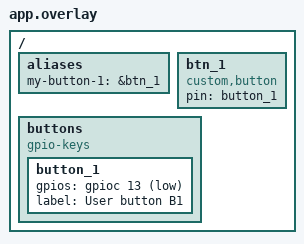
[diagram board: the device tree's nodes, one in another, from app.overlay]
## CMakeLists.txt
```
cmake_minimum_required(VERSION 3.20.0)

set(ZEPHYR_EXTRA_MODULES D:/zephyr_workspace/modules/button)

find_package(Zephyr REQUIRED HINTS $ENV{ZEPHYR_BASE})
project(button_driver)

target_sources(app PRIVATE src/main.c)
```

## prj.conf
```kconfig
CONFIG_GPIO=y
CONFIG_LOG=y
CONFIG_CUSTOM_BUTTON=y
```

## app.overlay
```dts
/ {
	aliases {
		my-button-1 = &btn_1;
	};

	btn_1: btn_1 {
		compatible = "custom,button";
		pin = <&button_1>;
	};

	buttons {
		compatible = "gpio-keys";

		button_1: button_1 {
			gpios = <&gpioc 13 (GPIO_ACTIVE_LOW | GPIO_PULL_UP)>;
			label = "User button B1";
		};
	};
};
```

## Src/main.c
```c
#include <stdio.h>
#include <zephyr/kernel.h>

#include "button.h"

static const int32_t sleep_time_ms = 500;
static const struct device *btn_1 = DEVICE_DT_GET(DT_ALIAS(my_button_1));

int main(void)
{
    int ret;
    uint8_t state_1;

    if (!device_is_ready(btn_1)) {
        printk("Error: button is not ready\r\n");
        return 0;
    }

    // Reach the driver through the device's api pointer
    const struct button_api *btn_api = (const struct button_api *)btn_1->api;

    while (1) {

        ret = btn_api->get(btn_1, &state_1);
        if (ret < 0) {
            printk("Error (%d): failed to read button pin\r\n", ret);
            continue;
        }

        printk("The State of the button is:%u\r\n", state_1);

        k_msleep(sleep_time_ms);
    }

    return 0;
}
```
